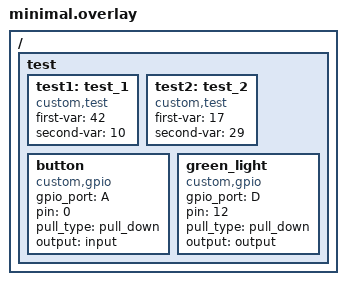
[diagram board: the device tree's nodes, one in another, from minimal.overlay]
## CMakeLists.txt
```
cmake_minimum_required(VERSION 3.22)

set(BOARD stm32f4_disco)

set(DTC_OVERLAY_FILE ${CMAKE_CURRENT_SOURCE_DIR}/minimal.overlay)
# set(ZEPHYR_EXTRA_MODULES "${CMAKE_SOURCE_DIR}/../../extra_modules/custom")
set(ZEPHYR_EXTRA_MODULES "${WEST_TOPDIR}/extra_modules/custom")

# message("Here: ${ZEPHYR_BASE}")
# message("There: ${WEST_TOPDIR}")

# Finds and loads packages from external project.
# Use the zephyr path.
find_package(Zephyr REQUIRED HINTS $ENV{ZEPHYR_BASE})
project(dts_test)

target_sources(app PRIVATE src/main.c)
```

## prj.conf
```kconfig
CONFIG_GPIO_DRIVER=y
CONFIG_TEST_DRIVER=y
```

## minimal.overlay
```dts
/ {
    test {

        test1: test_1 {
            compatible = "custom,test";
            first-var = <42>;
            second-var = <10>;
            status = "okay";
        };

        test2: test_2 {
            compatible = "custom,test";
            first-var = <17>;
            second-var = <29>;
            status = "okay";
        };

        button {
            compatible = "custom,gpio";
            gpio_port = "A";
            pin = <0>;
            pull_type = "pull_down";
            output = "input";
        };

        green_light {
            compatible = "custom,gpio";
            gpio_port = "D";
            pin = <12>;
            pull_type = "pull_down";
            output = "output";
        };
    };
};
```

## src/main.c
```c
#include <zephyr/kernel.h>
#include <zephyr/app_version.h>
#include <stdio.h>

#include "test.h"
#include "gpio.h"

// Get values for struct from device tree.
struct test_config first_test_config = EXAMPLE_DT_GET_TEST_BY_IDX(test1);
struct test_config second_test_config = EXAMPLE_DT_GET_TEST_BY_IDX(test2);

struct Gpio green = {
    .reg = DT_STRING_TOKEN(DT_PATH(test, green_light), gpio_port),
    .pin = DT_PROP(DT_PATH(test, green_light), pin),
    .pull = DT_STRING_TOKEN(DT_PATH(test, green_light), pull_type),
    .mode = DT_STRING_TOKEN(DT_PATH(test, green_light), output)
};

struct Gpio usr_button = {
    .reg = DT_STRING_TOKEN(DT_PATH(test, button), gpio_port),
    .pin = DT_PROP(DT_PATH(test, button), pin),
    .pull = DT_STRING_TOKEN(DT_PATH(test, button), pull_type),
    .mode = DT_STRING_TOKEN(DT_PATH(test, button), output)
};

int main(void) {
    init_gpio(green);
    init_gpio(usr_button);

    int pin_state = 1;
    write_pin(green, pin_state);

    while(1) {

        if (read_pin(usr_button)) {
            test_print();

            pin_state = !pin_state;
            write_pin(green, pin_state);

            // APP_VERSION_EXTENDED_STRING is a macro provided by Zephyr.
            // It is the extended string version format as read in VERSION file.
            printf("Version number: %s\n", APP_VERSION_EXTENDED_STRING);

            printf("First test config: %d\n", test_func(first_test_config));
            printf("Second test config: %d\n", test_func(second_test_config));

            if (DT_HAS_COMPAT_STATUS_OKAY(custom_compatible)) {
                printf("custom,compatible in device tree\n");
            }

            k_msleep(300);
            while (read_pin(usr_button));
        }
    }

    return 0;
}
```
